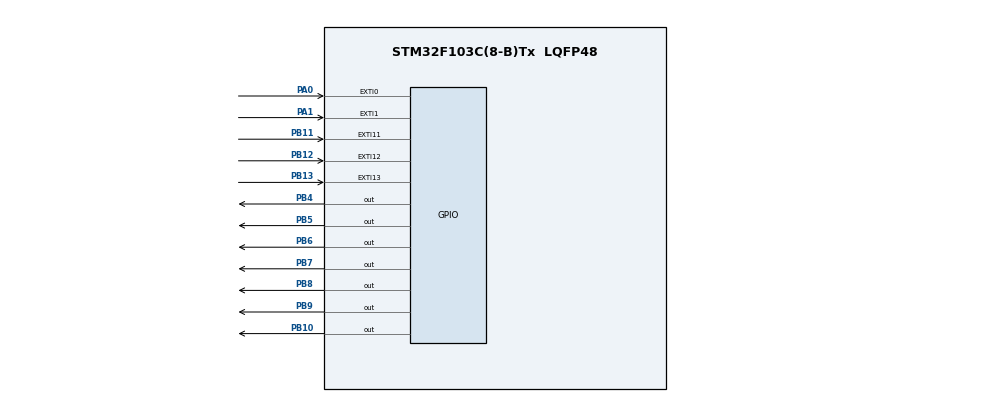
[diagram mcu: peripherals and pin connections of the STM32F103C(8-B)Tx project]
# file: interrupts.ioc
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Mcu.Family=STM32F1
Mcu.Name=STM32F103C(8-B)Tx
Mcu.Package=LQFP48
NVIC.EXTI0_IRQn=true\:0\:0\:false\:false\:true\:true\:true\:true
NVIC.EXTI15_10_IRQn=true\:0\:0\:false\:false\:true\:true\:true\:true
NVIC.EXTI1_IRQn=true\:0\:0\:false\:false\:true\:true\:true\:true
NVIC.PriorityGroup=NVIC_PRIORITYGROUP_4
PA0-WKUP.GPIO_ModeDefaultEXTI=GPIO_MODE_IT_RISING
PA0-WKUP.GPIO_PuPd=GPIO_PULLDOWN
PA0-WKUP.Signal=GPXTI0
PA1.GPIO_ModeDefaultEXTI=GPIO_MODE_IT_RISING
PA1.GPIO_PuPd=GPIO_PULLDOWN
PA1.Signal=GPXTI1
PA13.Mode=Serial_Wire
PA13.Signal=SYS_JTMS-SWDIO
PA14.Mode=Serial_Wire
PA14.Signal=SYS_JTCK-SWCLK
PB10.Signal=GPIO_Output
PB11.GPIO_ModeDefaultEXTI=GPIO_MODE_IT_RISING
PB11.GPIO_PuPd=GPIO_PULLDOWN
PB11.Signal=GPXTI11
PB12.GPIO_PuPd=GPIO_PULLDOWN
PB12.Signal=GPXTI12
PB13.GPIO_ModeDefaultEXTI=GPIO_MODE_IT_RISING
PB13.GPIO_PuPd=GPIO_PULLDOWN
PB13.Signal=GPXTI13
PB4.Signal=GPIO_Output
PB5.Signal=GPIO_Output
PB6.Signal=GPIO_Output
PB7.Signal=GPIO_Output
PB8.Signal=GPIO_Output
PB9.Signal=GPIO_Output
PD0-OSC_IN.Mode=HSE-External-Oscillator
PD0-OSC_IN.Signal=RCC_OSC_IN
PD1-OSC_OUT.Mode=HSE-External-Oscillator
PD1-OSC_OUT.Signal=RCC_OSC_OUT
ProjectManager.HeapSize=0x200
ProjectManager.StackSize=0x400
ProjectManager.TargetToolchain=STM32CubeIDE
RCC.APB1Freq_Value=8000000
RCC.APB2Freq_Value=8000000
RCC.SYSCLKSource=RCC_SYSCLKSOURCE_HSE
board=custom

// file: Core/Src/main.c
/* USER CODE BEGIN Header */
/**
  ******************************************************************************
  * @file           : main.c
  * @brief          : Main program body
  ******************************************************************************
  * @attention
  *
  * Copyright (c) 2022 STMicroelectronics.
  * All rights reserved.
  *
  * This software is licensed under terms that can be found in the LICENSE file
  * in the root directory of this software component.
  * If no LICENSE file comes with this software, it is provided AS-IS.
  *
  ******************************************************************************
  */
/* USER CODE END Header */
#include "main.h"

void SystemClock_Config(void);
static void MX_GPIO_Init(void);

#define mascara (uint32_t) 0b11100000000000
uint32_t display[]={0x3f,0x06,0x5b,0x4f,0x66,0x6d,0x7d,0x07,0x7f,0x67};
int32_t retraso=200;
uint32_t operacion=0;
int32_t numero=0;
int main(void)
{

  /* MCU Configuration--------------------------------------------------------*/

  /* Reset of all peripherals, Initializes the Flash interface and the Systick. */
  HAL_Init();

  /* Configure the system clock */
  SystemClock_Config();

  /* Initialize all configured peripherals */
  MX_GPIO_Init();

  /* Infinite loop */
  while (1)
  {
	  HAL_Delay(retraso);
	  if (operacion==1)
	   numero++;
	   else{
	   numero--;
	   }
	   if (numero>9) numero=0;
	   if (numero<0) numero=9;
	   GPIOB->ODR = (~mascara)&(display[numero]<<4);

  }
}

void SystemClock_Config(void)
{
  RCC_OscInitTypeDef RCC_OscInitStruct = {0};
  RCC_ClkInitTypeDef RCC_ClkInitStruct = {0};

  /** Initializes the RCC Oscillators according to the specified parameters
  * in the RCC_OscInitTypeDef structure.
  */
  RCC_OscInitStruct.OscillatorType = RCC_OSCILLATORTYPE_HSE;
  RCC_OscInitStruct.HSEState = RCC_HSE_ON;
  RCC_OscInitStruct.PLL.PLLState = RCC_PLL_NONE;
  if (HAL_RCC_OscConfig(&RCC_OscInitStruct) != HAL_OK)
  {
    Error_Handler();
  }

  /** Initializes the CPU, AHB and APB buses clocks
  */
  RCC_ClkInitStruct.ClockType = RCC_CLOCKTYPE_HCLK|RCC_CLOCKTYPE_SYSCLK
                              |RCC_CLOCKTYPE_PCLK1|RCC_CLOCKTYPE_PCLK2;
  RCC_ClkInitStruct.SYSCLKSource = RCC_SYSCLKSOURCE_HSE;
  RCC_ClkInitStruct.AHBCLKDivider = RCC_SYSCLK_DIV1;
  RCC_ClkInitStruct.APB1CLKDivider = RCC_HCLK_DIV1;
  RCC_ClkInitStruct.APB2CLKDivider = RCC_HCLK_DIV1;

  if (HAL_RCC_ClockConfig(&RCC_ClkInitStruct, FLASH_LATENCY_0) != HAL_OK)
  {
    Error_Handler();
  }
}

static void MX_GPIO_Init(void)
{
  GPIO_InitTypeDef GPIO_InitStruct = {0};

  /* GPIO Ports Clock Enable */
  __HAL_RCC_GPIOD_CLK_ENABLE();
  __HAL_RCC_GPIOA_CLK_ENABLE();
  __HAL_RCC_GPIOB_CLK_ENABLE();

  /*Configure GPIO pin Output Level */
  HAL_GPIO_WritePin(GPIOB, GPIO_PIN_10|GPIO_PIN_4|GPIO_PIN_5|GPIO_PIN_6
                          |GPIO_PIN_7|GPIO_PIN_8|GPIO_PIN_9, GPIO_PIN_RESET);

  /*Configure GPIO pins : PA0 PA1 */
  GPIO_InitStruct.Pin = GPIO_PIN_0|GPIO_PIN_1;
  GPIO_InitStruct.Mode = GPIO_MODE_IT_RISING;
  GPIO_InitStruct.Pull = GPIO_PULLDOWN;
  HAL_GPIO_Init(GPIOA, &GPIO_InitStruct);

  /*Configure GPIO pins : PB10 PB4 PB5 PB6
                           PB7 PB8 PB9 */
  GPIO_InitStruct.Pin = GPIO_PIN_10|GPIO_PIN_4|GPIO_PIN_5|GPIO_PIN_6
                          |GPIO_PIN_7|GPIO_PIN_8|GPIO_PIN_9;
  GPIO_InitStruct.Mode = GPIO_MODE_OUTPUT_PP;
  GPIO_InitStruct.Pull = GPIO_NOPULL;
  GPIO_InitStruct.Speed = GPIO_SPEED_FREQ_LOW;
  HAL_GPIO_Init(GPIOB, &GPIO_InitStruct);

  /*Configure GPIO pins : PB11 PB12 PB13 */
  GPIO_InitStruct.Pin = GPIO_PIN_11|GPIO_PIN_12|GPIO_PIN_13;
  GPIO_InitStruct.Mode = GPIO_MODE_IT_RISING;
  GPIO_InitStruct.Pull = GPIO_PULLDOWN;
  HAL_GPIO_Init(GPIOB, &GPIO_InitStruct);

  /* EXTI interrupt init*/
  HAL_NVIC_SetPriority(EXTI0_IRQn, 0, 0);
  HAL_NVIC_EnableIRQ(EXTI0_IRQn);

  HAL_NVIC_SetPriority(EXTI1_IRQn, 0, 0);
  HAL_NVIC_EnableIRQ(EXTI1_IRQn);

  HAL_NVIC_SetPriority(EXTI15_10_IRQn, 0, 0);
  HAL_NVIC_EnableIRQ(EXTI15_10_IRQn);

}

/* USER CODE BEGIN 4 */
void HAL_GPIO_EXTI_Callback(uint16_t GPIO_Pin)
{
if (GPIO_Pin==GPIO_PIN_11) retraso=1000;
	if (GPIO_Pin==GPIO_PIN_12) operacion=1;
	if (GPIO_Pin==GPIO_PIN_13) operacion=0;
	if (GPIO_Pin==GPIO_PIN_0) retraso=200;
	if (GPIO_Pin==GPIO_PIN_1) retraso=500;
}
/* USER CODE END 4 */

void Error_Handler(void)
{
  __disable_irq();
  while (1)
  {
  }
}
